# CC13x0 register map
File version: 2.0
CPU: CM3 r2p1, little endian, no MPU, no FPU, 0x3 interrupt priority bits, 0x0 interrupts
Registers are 32-bit, read-write, reset 0x0 unless marked. A register's access mark holds for its fields unless they carry their own. Offsets are from the block's base; [hi:lo] are bit positions.

## PRCM — Power, Reset and Clock Management
Base 0x40082000
0x00 INFRCLKDIVR — Infrastructure Clock Division Factor For Run Mode
  [1:0] RATIO
0x04 INFRCLKDIVS — Infrastructure Clock Division Factor For Sleep Mode
  [1:0] RATIO
0x08 INFRCLKDIVDS — Infrastructure Clock Division Factor For DeepSleep Mode
  [1:0] RATIO
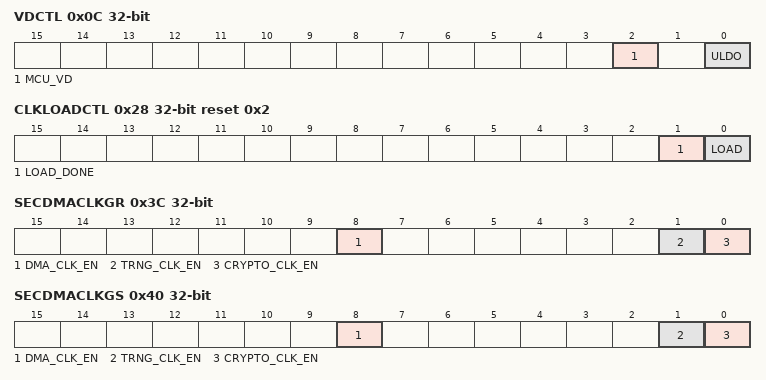
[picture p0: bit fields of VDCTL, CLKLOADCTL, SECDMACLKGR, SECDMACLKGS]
0x0C VDCTL — MCU Voltage Domain Control
  [2] MCU_VD, [0] ULDO
0x28 CLKLOADCTL reset 0x2 — Clock Load Control
  [1] LOAD_DONE, [0] LOAD
0x2C RFCCLKG reset 0x1 — RFC Clock Gate
  [0] CLK_EN
0x30 VIMSCLKG reset 0x3 — VIMS Clock Gate
  [1:0] CLK_EN
0x3C SECDMACLKGR — TRNG, CRYPTO And UDMA Clock Gate For Run Mode
  [8] DMA_CLK_EN, [1] TRNG_CLK_EN, [0] CRYPTO_CLK_EN
0x40 SECDMACLKGS — TRNG, CRYPTO And UDMA Clock Gate For Sleep Mode
  [8] DMA_CLK_EN, [1] TRNG_CLK_EN, [0] CRYPTO_CLK_EN
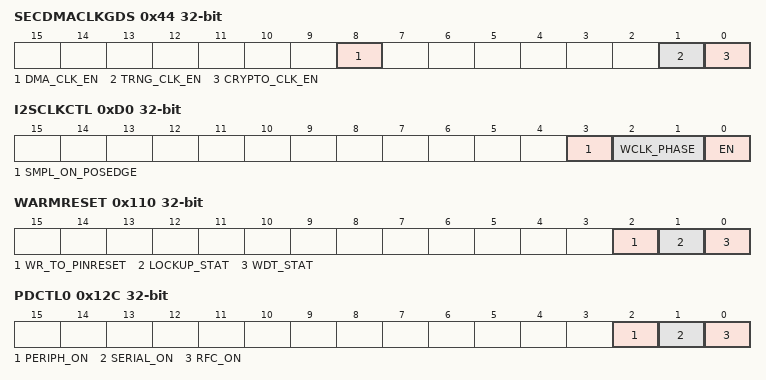
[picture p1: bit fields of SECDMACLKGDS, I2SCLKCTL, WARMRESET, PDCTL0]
0x44 SECDMACLKGDS — TRNG, CRYPTO And UDMA Clock Gate For Deep Sleep Mode
  [8] DMA_CLK_EN, [1] TRNG_CLK_EN, [0] CRYPTO_CLK_EN
0x48 GPIOCLKGR — GPIO Clock Gate For Run Mode
  [0] CLK_EN
0x4C GPIOCLKGS — GPIO Clock Gate For Sleep Mode
  [0] CLK_EN
0x50 GPIOCLKGDS — GPIO Clock Gate For Deep Sleep Mode
  [0] CLK_EN
0x54 GPTCLKGR — GPT Clock Gate For Run Mode
  [3:0] CLK_EN
0x58 GPTCLKGS — GPT Clock Gate For Sleep Mode
  [3:0] CLK_EN
0x5C GPTCLKGDS — GPT Clock Gate For Deep Sleep Mode
  [3:0] CLK_EN
0x60 I2CCLKGR — I2C Clock Gate For Run Mode
  [0] CLK_EN
0x64 I2CCLKGS — I2C Clock Gate For Sleep Mode
  [0] CLK_EN
0x68 I2CCLKGDS — I2C Clock Gate For Deep Sleep Mode
  [0] CLK_EN
0x6C UARTCLKGR — UART Clock Gate For Run Mode
  [0] CLK_EN
0x70 UARTCLKGS — UART Clock Gate For Sleep Mode
  [0] CLK_EN
0x74 UARTCLKGDS — UART Clock Gate For Deep Sleep Mode
  [0] CLK_EN
0x78 SSICLKGR — SSI Clock Gate For Run Mode
  [1:0] CLK_EN
0x7C SSICLKGS — SSI Clock Gate For Sleep Mode
  [1:0] CLK_EN
0x80 SSICLKGDS — SSI Clock Gate For Deep Sleep Mode
  [1:0] CLK_EN
0x84 I2SCLKGR — I2S Clock Gate For Run Mode
  [0] CLK_EN
0x88 I2SCLKGS — I2S Clock Gate For Sleep Mode
  [0] CLK_EN
0x8C I2SCLKGDS — I2S Clock Gate For Deep Sleep Mode
  [0] CLK_EN
0xB8 CPUCLKDIV — Internal. Only to be used through TI provided API.
  [0] RATIO
0xC8 I2SBCLKSEL — I2S Clock Control
  [0] SRC
0xCC GPTCLKDIV — GPT Scalar
  [3:0] RATIO
0xD0 I2SCLKCTL — I2S Clock Control
  [3] SMPL_ON_POSEDGE, [2:1] WCLK_PHASE, [0] EN
0xD4 I2SMCLKDIV — MCLK Division Ratio
  [9:0] MDIV
0xD8 I2SBCLKDIV — BCLK Division Ratio
  [9:0] BDIV
0xDC I2SWCLKDIV — WCLK Division Ratio
  [15:0] WDIV
0x10C SWRESET — SW Initiated Resets
  [2] MCU
0x110 WARMRESET — WARM Reset Control And Status
  [2] WR_TO_PINRESET, [1] LOCKUP_STAT, [0] WDT_STAT
0x12C PDCTL0 — Power Domain Control
  [2] PERIPH_ON, [1] SERIAL_ON, [0] RFC_ON
0x130 PDCTL0RFC — RFC Power Domain Control
  [0] ON
0x134 PDCTL0SERIAL — SERIAL Power Domain Control
  [0] ON
0x138 PDCTL0PERIPH — PERIPH Power Domain Control
  [0] ON
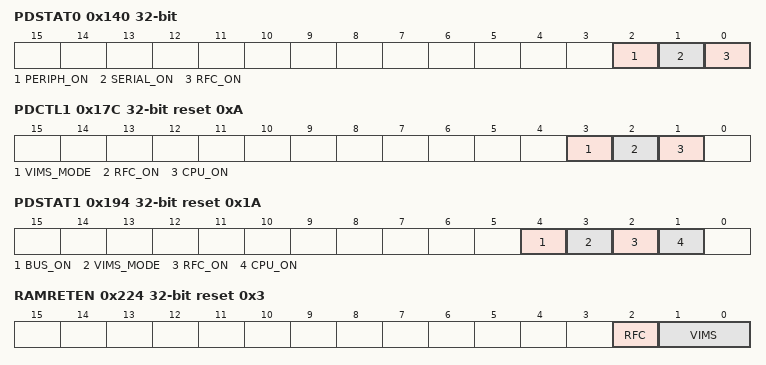
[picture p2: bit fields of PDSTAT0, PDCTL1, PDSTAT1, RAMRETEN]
0x140 PDSTAT0 ro — Power Domain Status
  [2] PERIPH_ON, [1] SERIAL_ON, [0] RFC_ON
0x144 PDSTAT0RFC ro — RFC Power Domain Status
  [0] ON
0x148 PDSTAT0SERIAL ro — SERIAL Power Domain Status
  [0] ON
0x14C PDSTAT0PERIPH ro — PERIPH Power Domain Status
  [0] ON
0x17C PDCTL1 reset 0xA — Power Domain Control
  [3] VIMS_MODE, [2] RFC_ON, [1] CPU_ON
0x184 PDCTL1CPU reset 0x1 — CPU Power Domain Control
  [0] ON
0x188 PDCTL1RFC — RFC Power Domain Control
  [0] ON
0x18C PDCTL1VIMS reset 0x1 — VIMS Power Domain Control
  [0] ON
0x194 PDSTAT1 ro reset 0x1A — Power Domain Status
  [4] BUS_ON, [3] VIMS_MODE, [2] RFC_ON, [1] CPU_ON
0x198 PDSTAT1BUS ro reset 0x1 — BUS Power Domain Status
  [0] ON
0x19C PDSTAT1RFC ro — RFC Power Domain Status
  [0] ON
0x1A0 PDSTAT1CPU ro reset 0x1 — CPU Power Domain Status
  [0] ON
0x1A4 PDSTAT1VIMS ro reset 0x1 — VIMS Power Domain Status
  [0] ON
0x1D0 RFCMODESEL — Selected RFC Mode
  [2:0] CURR
0x224 RAMRETEN reset 0x3 — Memory Retention Control
  [2] RFC, [1:0] VIMS
